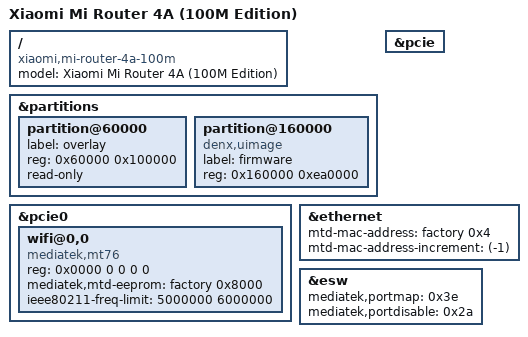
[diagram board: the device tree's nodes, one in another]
// SPDX-License-Identifier: GPL-2.0-or-later OR MIT

#include "mt7628an_xiaomi_mi-router-4.dtsi"

/ {
	compatible = "xiaomi,mi-router-4a-100m", "mediatek,mt7628an-soc";
	model = "Xiaomi Mi Router 4A (100M Edition)";
};

&partitions {
	partition@60000 {
		label = "overlay";
		reg = <0x60000 0x100000>;
		read-only;
	};

	partition@160000 {
		label = "firmware";
		reg = <0x160000 0xea0000>;
		compatible = "denx,uimage";
	};
};

&pcie {
	status = "okay";
};

&pcie0 {
	wifi@0,0 {
		compatible = "mediatek,mt76";
		reg = <0x0000 0 0 0 0>;
		mediatek,mtd-eeprom = <&factory 0x8000>;
		ieee80211-freq-limit = <5000000 6000000>;
	};
};

&ethernet {
	mtd-mac-address = <&factory 0x4>;
	mtd-mac-address-increment = <(-1)>;
};

&esw {
	mediatek,portmap = <0x3e>;
	mediatek,portdisable = <0x2a>;
};
